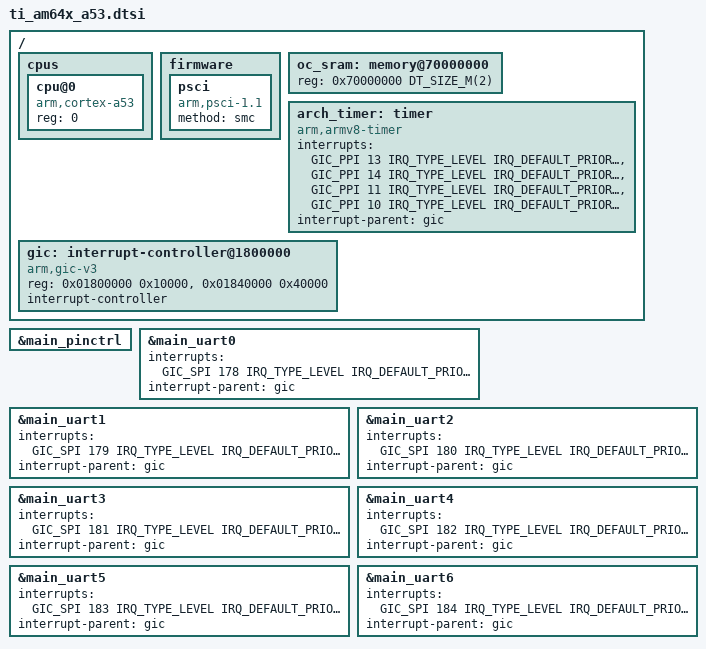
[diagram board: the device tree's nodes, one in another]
/*
 * Copyright (c) 2026 Texas Instruments Incorporated
 *
 * SPDX-License-Identifier: Apache-2.0
 */

#include <mem.h>
#include <freq.h>
#include <arm64/armv8-a.dtsi>
#include <zephyr/dt-bindings/interrupt-controller/arm-gic.h>
#include <zephyr/dt-bindings/pinctrl/ti-k3-pinctrl.h>
#include <ti/am64x_main.dtsi>

/ {
	#address-cells = <1>;
	#size-cells = <1>;

	cpus {
		#address-cells = <1>;
		#size-cells = <0>;

		cpu@0 {
			device_type = "cpu";
			compatible = "arm,cortex-a53";
			reg = <0>;
		};
	};

	firmware {
		psci: psci {
			compatible = "arm,psci-1.1";
			method = "smc";
		};
	};

	/* MSRAM, 8 x 256KB banks (TRM Table 2-1) */
	oc_sram: memory@70000000 {
		reg = <0x70000000 DT_SIZE_M(2)>;
	};

	/* Secure phys 13, non-secure phys 14, virt 11, hyp 10 (TRM Table 6-4) */
	arch_timer: timer {
		compatible = "arm,armv8-timer";
		interrupts = <GIC_PPI 13 IRQ_TYPE_LEVEL IRQ_DEFAULT_PRIORITY>,
			     <GIC_PPI 14 IRQ_TYPE_LEVEL IRQ_DEFAULT_PRIORITY>,
			     <GIC_PPI 11 IRQ_TYPE_LEVEL IRQ_DEFAULT_PRIORITY>,
			     <GIC_PPI 10 IRQ_TYPE_LEVEL IRQ_DEFAULT_PRIORITY>;
		interrupt-parent = <&gic>;
	};

	/* GIC-500: TRM Table 9-7; 2 redistributors of 128KB (RD + SGI frames) */
	gic: interrupt-controller@1800000 {
		compatible = "arm,gic-v3", "arm,gic";
		reg = <0x01800000 0x10000>, /* GICD */
		      <0x01840000 0x40000>; /* GICR */
		interrupt-controller;
		#interrupt-cells = <4>;
		status = "okay";
	};
};

&main_pinctrl {
	status = "okay";
};

/* GIC SPI n = INTID 32 + n; TRM lists UARTn on GICSS0_SPI_IN_(210 + n) */

&main_uart0 {
	interrupts = <GIC_SPI 178 IRQ_TYPE_LEVEL IRQ_DEFAULT_PRIORITY>;
	interrupt-parent = <&gic>;
};

&main_uart1 {
	interrupts = <GIC_SPI 179 IRQ_TYPE_LEVEL IRQ_DEFAULT_PRIORITY>;
	interrupt-parent = <&gic>;
};

&main_uart2 {
	interrupts = <GIC_SPI 180 IRQ_TYPE_LEVEL IRQ_DEFAULT_PRIORITY>;
	interrupt-parent = <&gic>;
};

&main_uart3 {
	interrupts = <GIC_SPI 181 IRQ_TYPE_LEVEL IRQ_DEFAULT_PRIORITY>;
	interrupt-parent = <&gic>;
};

&main_uart4 {
	interrupts = <GIC_SPI 182 IRQ_TYPE_LEVEL IRQ_DEFAULT_PRIORITY>;
	interrupt-parent = <&gic>;
};

&main_uart5 {
	interrupts = <GIC_SPI 183 IRQ_TYPE_LEVEL IRQ_DEFAULT_PRIORITY>;
	interrupt-parent = <&gic>;
};

&main_uart6 {
	interrupts = <GIC_SPI 184 IRQ_TYPE_LEVEL IRQ_DEFAULT_PRIORITY>;
	interrupt-parent = <&gic>;
};
